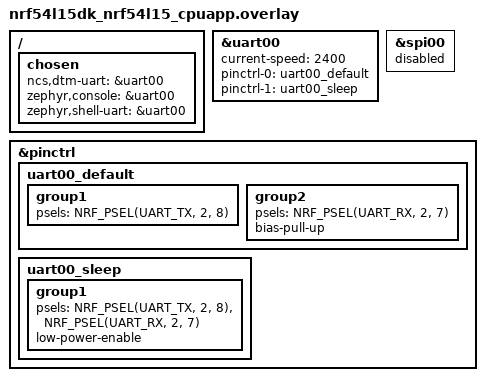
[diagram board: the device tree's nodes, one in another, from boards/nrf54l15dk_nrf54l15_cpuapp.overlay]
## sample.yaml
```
sample:
  description: Radio Test sample
  name: Radio Test
tests:
  sample.peripheral.radio_test:
    sysbuild: true
    build_only: true
    integration_platforms:
      - nrf52dk/nrf52832
      - nrf52840dk/nrf52840
      - nrf5340dk/nrf5340/cpunet
      - nrf7002dk/nrf5340/cpunet
      - nrf54l15dk/nrf54l05/cpuapp
      - nrf54l15dk/nrf54l10/cpuapp
      - nrf54l15dk/nrf54l15/cpuapp
      - nrf54h20dk/nrf54h20/cpurad
    platform_allow: >
      nrf52dk/nrf52832 nrf52840dk/nrf52840 nrf5340dk/nrf5340/cpunet nrf7002dk/nrf5340/cpunet
      nrf54l15dk/nrf54l05/cpuapp nrf54l15dk/nrf54l10/cpuapp nrf54l15dk/nrf54l15/cpuapp
      nrf54h20dk/nrf54h20/cpurad
    tags: ci_build sysbuild ci_samples_peripheral_radio_test
  sample.peripheral.radio_test.nrf5340_nrf21540:
    sysbuild: true
    build_only: true
    extra_args: SHIELD=nrf21540ek
    integration_platforms:
      - nrf5340dk/nrf5340/cpunet
    platform_allow: nrf5340dk/nrf5340/cpunet
    tags: ci_build sysbuild ci_samples_peripheral_radio_test
  sample.peripheral.radio_test.nrf5340_usb:
    sysbuild: true
    build_only: true
    extra_args: FILE_SUFFIX=usb
    integration_platforms:
      - nrf5340dk/nrf5340/cpunet
    platform_allow: nrf5340dk/nrf5340/cpunet
    tags: ci_build sysbuild ci_samples_peripheral_radio_test
  sample.peripheral.radio_test.nrf5340_nrf21540_usb:
    sysbuild: true
    build_only: true
    extra_args: SHIELD=nrf21540ek FILE_SUFFIX=usb
    integration_platforms:
      - nrf5340dk/nrf5340/cpunet
    platform_allow: nrf5340dk/nrf5340/cpunet
    tags: ci_build sysbuild ci_samples_peripheral_radio_test
  sample.peripheral.radio_test.nrf5340_nrf21540.no_automatic_power:
    sysbuild: true
    build_only: true
    extra_args: SHIELD=nrf21540ek
    extra_configs:
      - CONFIG_RADIO_TEST_POWER_CONTROL_AUTOMATIC=n
    integration_platforms:
      - nrf5340dk/nrf5340/cpunet
    platform_allow: nrf5340dk/nrf5340/cpunet
    tags: ci_build sysbuild ci_samples_peripheral_radio_test
```

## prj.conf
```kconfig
#
# Copyright (c) 2020 Nordic Semiconductor
#
# SPDX-License-Identifier: LicenseRef-Nordic-5-Clause
#

# 啟用 RTT shell
#CONFIG_USE_SEGGER_RTT=y
#CONFIG_SHELL_BACKEND_RTT=y

# 停用 UART shell（因為你沒有接 UART）
##CONFIG_SHELL_BACKEND_SERIAL=n

CONFIG_CONSOLE_HANDLER=y
CONFIG_SHELL=y

#CONFIG_SHELL_HISTORY=y
#CONFIG_SHELL_CMDS=y
#CONFIG_SHELL_HELP=y
#CONFIG_SHELL_VT100_COLORS=y

CONFIG_DYNAMIC_INTERRUPTS=y

CONFIG_NRFX_TIMER0=y
CONFIG_CLOCK_CONTROL=y

CONFIG_ENTROPY_GENERATOR=y
CONFIG_NRF_SECURITY=y

CONFIG_FEM_AL_LIB=y
CONFIG_PICOLIBC_IO_FLOAT=y
```

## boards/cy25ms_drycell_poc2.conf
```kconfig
#
# Copyright (c) 2023 Nordic Semiconductor
#
# SPDX-License-Identifier: LicenseRef-Nordic-5-Clause
#

# Disable the unsupported driver
CONFIG_NRFX_TIMER0=n

# Enable the necessary drivers
CONFIG_NRFX_TIMER10=y
CONFIG_NRFX_DPPI=y

CONFIG_SOC_NRF54L_VREG_MAIN_DCDC=y
CONFIG_SOC_NRF54L_NORMAL_VOLTAGE_MODE=y

CONFIG_CLOCK_CONTROL_NRF_K32SRC_RC=y
CONFIG_CLOCK_CONTROL_NRF_K32SRC_XTAL=n
CONFIG_CLOCK_CONTROL_NRF_K32SRC_500PPM=y
```

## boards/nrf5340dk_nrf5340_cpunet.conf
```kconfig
#
# Copyright (c) 2022 Nordic Semiconductor
#
# SPDX-License-Identifier: LicenseRef-Nordic-5-Clause
#

CONFIG_CONSOLE_HANDLER=n
CONFIG_CONSOLE=n
CONFIG_SERIAL=n
CONFIG_UART_CONSOLE=n

CONFIG_SHELL_IPC=y
CONFIG_SHELL_LOG_BACKEND=y
CONFIG_SHELL_BACKEND_SERIAL=n
CONFIG_SHELL_PROMPT_IPC="radio_test:~$ "

CONFIG_LOG=y
CONFIG_LOG_PRINTK=y

CONFIG_MBOX=y
CONFIG_IPC_SERVICE=y
CONFIG_IPC_SERVICE_BACKEND_RPMSG=y

CONFIG_HEAP_MEM_POOL_SIZE=4096

CONFIG_NCS_SAMPLE_REMOTE_SHELL_CHILD_IMAGE=y
```

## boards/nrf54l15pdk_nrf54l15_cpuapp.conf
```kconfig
#
# Copyright (c) 2023 Nordic Semiconductor
#
# SPDX-License-Identifier: LicenseRef-Nordic-5-Clause
#

# Disable the unsupported driver
CONFIG_NRFX_TIMER0=n

# Enable the necessary drivers
CONFIG_NRFX_TIMER10=y
CONFIG_NRFX_GPPI=y
```

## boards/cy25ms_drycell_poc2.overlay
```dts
&uart20 {
	status = "okay";
	current-speed = <115200>;
	/delete-property/ hw-flow-control;
};

&hfxo {
	load-capacitors = "internal";
	load-capacitance-femtofarad = <12000>;
/*	load-capacitance-femtofarad = <8000>;
	load-capacitance-femtofarad = <12000>;
	load-capacitance-femtofarad = <14000>;
	load-capacitance-femtofarad = <15000>;
	load-capacitance-femtofarad = <16000>;
*/
};

&pinctrl {
	uart20_default: uart20_default {
		group1 {
			psels = <NRF_PSEL(UART_TX, 1, 10)>;
		};
		group2 {
			psels = <NRF_PSEL(UART_RX, 1, 9)>;
			bias-pull-up;
		};
	};

	uart20_sleep: uart20_sleep {
		group1 {
			psels = <NRF_PSEL(UART_TX, 1, 10)>,
					<NRF_PSEL(UART_RX, 1, 9)>;
			low-power-enable;
		};
	};
};

&radio {
	status = "okay";
	/* This is a number of antennas that are available on antenna matrix
	 * designed by Nordic. For more information see README.rst.
	 */
	dfe-antenna-num = <12>;
	/* This is a setting that enables antenna 12 (in antenna matrix designed
	 * by Nordic) for PDU. For more information see README.rst.
	 */
	dfe-pdu-antenna = <0x0>;

	/* These are GPIO pin numbers that are provided to
	 * Radio peripheral. The pins will be acquired by Radio to
	 * drive antenna switching.
	 * Pin numbers are selected to drive switches on antenna matrix
	 * desinged by Nordic. For more information see README.rst.
	 */
	dfegpio0-gpios = <&gpio0 4 0>;
	dfegpio1-gpios = <&gpio0 5 0>;
	dfegpio2-gpios = <&gpio0 6 0>;
	dfegpio3-gpios = <&gpio0 7 0>;
};
```

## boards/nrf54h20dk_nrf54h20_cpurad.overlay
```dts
/*
 * Copyright (c) 2024 Nordic Semiconductor ASA
 *
 * SPDX-License-Identifier: LicenseRef-Nordic-5-Clause
 */

 /{
	chosen {
		zephyr,console = &uart136;
		zephyr,shell-uart = &uart136;
	};
};

&uart135 {
	status = "disabled";
};

&cpurad_dma_region {
	status = "disabled";
};

/* Take Application's DMA region, which is larger and unused. */
cpurad_dma_region_alt: &cpuapp_dma_region {
	status = "okay";
	nordic,access = <NRF_OWNER_ID_RADIOCORE NRF_PERM_RW>;
};

&uart136 {
	status = "okay";
	memory-regions = <&cpurad_dma_region_alt>;
};

&dppic020 {
	status = "okay";
	source-channels = < 0 1 >;
	sink-channels = < 2 3 >;
};
```

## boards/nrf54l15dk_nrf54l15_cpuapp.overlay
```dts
/*
* Copyright (c) 2024 Nordic Semiconductor ASA
*
* SPDX-License-Identifier: LicenseRef-Nordic-5-Clause
*/

/ {
  chosen {
                 ncs,dtm-uart = &uart00;
                 zephyr,console = &uart00;
                 zephyr,shell-uart = &uart00;
  };
};

&uart00 {
  status = "okay";
  current-speed = <2400>;
  pinctrl-0 = < &uart00_default >;
  pinctrl-1 = < &uart00_sleep >;
  pinctrl-names = "default", "sleep";
  /delete-property/ hw-flow-control;
};

&spi00 {
  status = "disabled";
};

&pinctrl {
 uart00_default: uart00_default {
                 group1 {
                               psels = <NRF_PSEL(UART_TX, 2, 8)>;
                 };
                 group2 {
                               psels = <NRF_PSEL(UART_RX, 2, 7)>;
                               bias-pull-up;
                 };
 };

 uart00_sleep: uart00_sleep {
                 group1 {
                               psels = <NRF_PSEL(UART_TX, 2, 8)>,
                                              <NRF_PSEL(UART_RX, 2, 7)>;
                               low-power-enable;
                 };
 };
};
```

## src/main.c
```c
/*
 * Copyright (c) 2020 Nordic Semiconductor ASA
 *
 * SPDX-License-Identifier: LicenseRef-Nordic-5-Clause
 */

#include <zephyr/sys/printk.h>
#include <zephyr/drivers/clock_control.h>
#include <zephyr/drivers/clock_control/nrf_clock_control.h>
#if defined(NRF54L15_XXAA)
#include <hal/nrf_clock.h>
#endif /* defined(NRF54L15_XXAA) */
#if defined(CONFIG_CLOCK_CONTROL_NRF2)
#include <hal/nrf_lrcconf.h>
#endif

#if defined(CONFIG_CLOCK_CONTROL_NRF)
static void clock_init(void)
{
	int err;
	int res;
	struct onoff_manager *clk_mgr;
	struct onoff_client clk_cli;

	clk_mgr = z_nrf_clock_control_get_onoff(CLOCK_CONTROL_NRF_SUBSYS_HF);
	if (!clk_mgr) {
		printk("Unable to get the Clock manager\n");
		return;
	}

	sys_notify_init_spinwait(&clk_cli.notify);

	err = onoff_request(clk_mgr, &clk_cli);
	if (err < 0) {
		printk("Clock request failed: %d\n", err);
		return;
	}

	do {
		err = sys_notify_fetch_result(&clk_cli.notify, &res);
		if (!err && res) {
			printk("Clock could not be started: %d\n", res);
			return;
		}
	} while (err);

#if defined(NRF54L15_XXAA)
	/* MLTPAN-20 */
	nrf_clock_task_trigger(NRF_CLOCK, NRF_CLOCK_TASK_PLLSTART);
#endif /* defined(NRF54L15_XXAA) */

	printk("Clock has started\n");
}

#elif defined(CONFIG_CLOCK_CONTROL_NRF2)

static void clock_init(void)
{
	int err;
	int res;
	const struct device *radio_clk_dev =
		DEVICE_DT_GET_OR_NULL(DT_CLOCKS_CTLR(DT_NODELABEL(radio)));
	struct onoff_client radio_cli;

	/** Keep radio domain powered all the time to reduce latency. */
	nrf_lrcconf_poweron_force_set(NRF_LRCCONF010, NRF_LRCCONF_POWER_DOMAIN_1, true);

	sys_notify_init_spinwait(&radio_cli.notify);

	err = nrf_clock_control_request(radio_clk_dev, NULL, &radio_cli);

	do {
		err = sys_notify_fetch_result(&radio_cli.notify, &res);
		if (!err && res) {
			printk("Clock could not be started: %d\n", res);
			return;
		}
	} while (err == -EAGAIN);

#if defined(NRF54L15_XXAA)
	/* MLTPAN-20 */
	nrf_clock_task_trigger(NRF_CLOCK, NRF_CLOCK_TASK_PLLSTART);
#endif /* defined(NRF54L15_XXAA) */

	printk("Clock has started\n");
}

#else
BUILD_ASSERT(false, "No Clock Control driver");
#endif /* defined(CONFIG_CLOCK_CONTROL_NRF) */

int main(void)
{
	printk("Starting Radio Test example\n");

	clock_init();

#if defined(CONFIG_SOC_SERIES_NRF54HX)
	/* Apply HMPAN-102 workaround for nRF54H series */
	*(volatile uint32_t *)0x5302C7E4 =
				(((*((volatile uint32_t *)0x5302C7E4)) & 0xFF000FFF) | 0x0012C000);
#endif

	return 0;
}
```

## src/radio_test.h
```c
/*
 * Copyright (c) 2020 Nordic Semiconductor ASA
 *
 * SPDX-License-Identifier: LicenseRef-Nordic-5-Clause
 */

#ifndef RADIO_TEST_H_
#define RADIO_TEST_H_

#include <zephyr/types.h>
#include <hal/nrf_radio.h>
#include <fem_al/fem_al.h>

#ifdef NRF53_SERIES
#ifndef RADIO_TXPOWER_TXPOWER_Pos3dBm
	#define RADIO_TXPOWER_TXPOWER_Pos3dBm (0x03UL)
#endif /* RADIO_TXPOWER_TXPOWER_Pos3dBm */

#ifndef RADIO_TXPOWER_TXPOWER_Pos2dBm
	#define RADIO_TXPOWER_TXPOWER_Pos2dBm (0x02UL)
#endif /* RADIO_TXPOWER_TXPOWER_Pos2dBm */

#ifndef RADIO_TXPOWER_TXPOWER_Pos1dBm
	#define RADIO_TXPOWER_TXPOWER_Pos1dBm (0x01UL)
#endif /* RADIO_TXPOWER_TXPOWER_Pos1dBm */
#endif /* NRF53_SERIES */

/** Maximum radio RX or TX payload. */
#define RADIO_MAX_PAYLOAD_LEN	256
/** IEEE 802.15.4 maximum payload length. */
#define IEEE_MAX_PAYLOAD_LEN	127
/** IEEE 802.15.4 minimum channel. */
#define IEEE_MIN_CHANNEL	11
/** IEEE 802.15.4 maximum channel. */
#define IEEE_MAX_CHANNEL	26

#define FEM_USE_DEFAULT_TX_POWER_CONTROL 0xFF

/**@brief Radio transmit and address pattern. */
enum transmit_pattern {
	/** Random pattern. */
	TRANSMIT_PATTERN_RANDOM,

	/** Pattern 11110000(F0). */
	TRANSMIT_PATTERN_11110000,

	/** Pattern 11001100(CC). */
	TRANSMIT_PATTERN_11001100,
};

/**@brief Radio test mode. */
enum radio_test_mode {
	/** TX carrier. */
	UNMODULATED_TX,

	/** Modulated TX carrier. */
	MODULATED_TX,

	/** RX carrier. */
	RX,

	/** TX carrier sweep. */
	TX_SWEEP,

	/** RX carrier sweep. */
	RX_SWEEP,

	/** Duty-cycled modulated TX carrier. */
	MODULATED_TX_DUTY_CYCLE,
};

/**@brief Radio test front-end module (FEM) configuration */
struct radio_test_fem {
	/* Front-end module radio ramp-up time in microseconds. */
	uint32_t ramp_up_time;

	/* Front-end module TX power control specific to given front-end module.
	 * For nRF21540 GPIO/SPI, this is a register value.
	 * For nRF21540 GPIO, this is MODE pin value.
	 */
	fem_tx_power_control tx_power_control;
};

/**@brief Radio test configuration. */
struct radio_test_config {
	/** Radio test type. */
	enum radio_test_mode type;

	/** Radio mode. Data rate and modulation. */
	nrf_radio_mode_t mode;

	union {
		struct {
			/** Radio output power. */
			int8_t txpower;

			/** Radio channel. */
			uint8_t channel;
		} unmodulated_tx;

		struct {
			/** Radio output power. */
			int8_t txpower;

			/** Radio transmission pattern. */
			enum transmit_pattern pattern;

			/** Radio channel. */
			uint8_t channel;

			/**
			 * Number of packets to transmit.
			 * Set to zero for continuous TX.
			 */
			uint32_t packets_num;

			/** Callback to indicate that TX is finished. */
			void (*cb)(void);
		} modulated_tx;

		struct {
			/** Radio transmission pattern. */
			enum transmit_pattern pattern;

			/** Radio channel. */
			uint8_t channel;

			/**
			 * Number of packets to be received.
			 * Set to zero for continuous RX.
			 */
			uint32_t packets_num;

			/** Callback to indicate that RX is finished. */
			void (*cb)(void);
		} rx;

		struct {
			/** Radio output power. */
			int8_t txpower;

			/** Radio start channel (frequency). */
			uint8_t channel_start;

			/** Radio end channel (frequency). */
			uint8_t channel_end;

			/** Delay time in milliseconds. */
			uint32_t delay_ms;
		} tx_sweep;

		struct {
			/** Radio start channel (frequency). */
			uint8_t channel_start;

			/** Radio end channel (frequency). */
			uint8_t channel_end;

			/** Delay time in milliseconds. */
			uint32_t delay_ms;
		} rx_sweep;

		struct {
			/** Radio output power. */
			int8_t txpower;

			/** Radio transmission pattern. */
			enum transmit_pattern pattern;

			/** Radio channel. */
			uint8_t channel;

			/** Duty cycle. */
			uint32_t duty_cycle;
		} modulated_tx_duty_cycle;
	} params;

#if CONFIG_FEM
	/* Front-end module (FEM) configuration. */
	struct radio_test_fem fem;
#endif /* CONFIG_FEM */
};

/**@brief Radio RX statistics. */
struct radio_rx_stats {
	/** Content of the last packet. */
	struct {
		/** Content of the last packet. */
		uint8_t *buf;

		/** Length of the last packet. */
		size_t len;
	} last_packet;

	/** Number of received packets with valid CRC. */
	uint32_t packet_cnt;
};

/**
 * @brief Function for initializing the Radio Test module.
 *
 * @param[in] config  Radio test configuration.
 *
 * @retval 0 If the operation was successful.
 *           Otherwise, a (negative) error code is returned.
 */
int radio_test_init(struct radio_test_config *config);

/**
 * @brief Function for starting radio test.
 *
 * @param[in] config  Radio test configuration.
 */
void radio_test_start(const struct radio_test_config *config);

/**
 * @brief Function for stopping ongoing test (Radio and Timer operations).
 */
void radio_test_cancel(void);

/**
 * @brief Function for get RX statistics.
 *
 * @param[out] rx_stats RX statistics.
 */
void radio_rx_stats_get(struct radio_rx_stats *rx_stats);

/**
 * @brief Function for toggling the DC/DC converter state.
 *
 * @param[in] dcdc_state  DC/DC converter state.
 */
void toggle_dcdc_state(uint8_t dcdc_state);

#endif /* RADIO_TEST_H_ */
```
